# STM32H73x register map
File version: 1.0
CPU: CM7 r0p1, little endian, MPU, FPU, 4 interrupt priority bits
Registers are 32-bit, read-write, reset 0x0 unless marked. A register's access mark holds for its fields unless they carry their own. Offsets are from the block's base; [hi:lo] are bit positions; {n}, {i} and the like mark numbered series; 'fields as' and 'values as' point back to an identical list.

## STK — SysTick timer
Base 0xE000E010
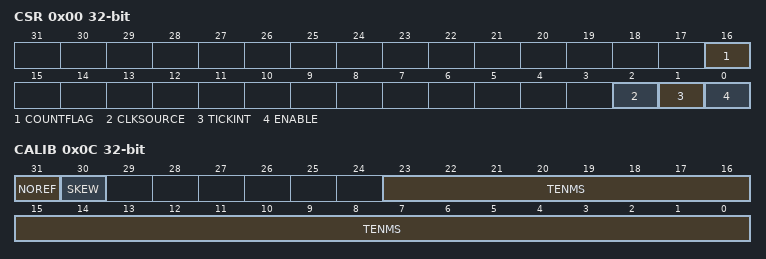
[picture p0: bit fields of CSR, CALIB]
0x00 CSR — SysTick control and status register
  [16] COUNTFLAG
  [2] CLKSOURCE — Clock source selection
  [1] TICKINT — SysTick exception request enable
  [0] ENABLE — Counter enable
0x04 RVR — SysTick reload value register
  [23:0] RELOAD — RELOAD value
0x08 CVR — SysTick current value register
  [23:0] CURRENT — Current counter value
0x0C CALIB — SysTick calibration value register
  [31] NOREF — NOREF flag. Reads as zero
  [30] SKEW — SKEW flag: Indicates whether the TENMS value is exact
  [23:0] TENMS — Calibration value

## NVIC_STIR — Nested vectored interrupt controller
Base 0xE000EF00
0x00 STIR — Software trigger interrupt register
  [8:0] INTID — Software generated interrupt ID

## FPU_CPACR — Floating point unit CPACR
Base 0xE000ED88
0x00 CPACR — Coprocessor access control register
  [23:20] CP

## SCB_ACTRL — System control block ACTLR
Base 0xE000E008
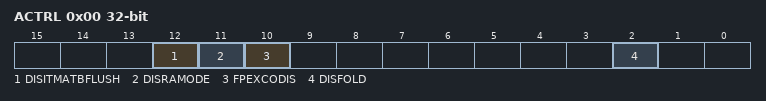
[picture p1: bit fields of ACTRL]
0x00 ACTRL — Auxiliary control register
  [12] DISITMATBFLUSH, [11] DISRAMODE, [10] FPEXCODIS, [2] DISFOLD

## FPU — Floting point unit
Base 0xE000EF34
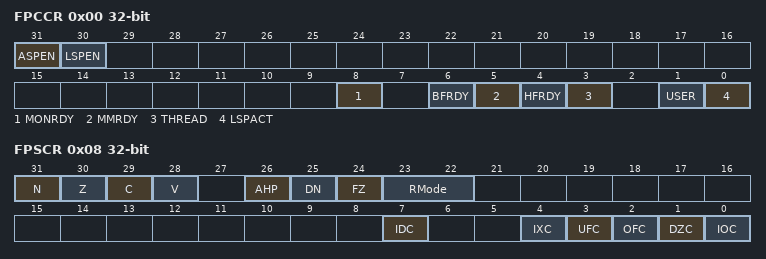
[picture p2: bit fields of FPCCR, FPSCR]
0x00 FPCCR — Floating-point context control register
  [31] ASPEN, [30] LSPEN, [8] MONRDY, [6] BFRDY, [5] MMRDY, [4] HFRDY, [3] THREAD, [1] USER, [0] LSPACT
0x04 FPCAR — Floating-point context address register
  [31:3] ADDRESS — Location of unpopulated floating-point
0x08 FPSCR — Floating-point status control register
  [31] N — Negative condition code flag
  [30] Z — Zero condition code flag
  [29] C — Carry condition code flag
  [28] V — Overflow condition code flag
  [26] AHP — Alternative half-precision control bit
  [25] DN — Default NaN mode control bit
  [24] FZ — Flush-to-zero mode control bit:
  [23:22] RMode — Rounding Mode control field
  [7] IDC — Input denormal cumulative exception bit.
  [4] IXC — Inexact cumulative exception bit
  [3] UFC — Underflow cumulative exception bit
  [2] OFC — Overflow cumulative exception bit
  [1] DZC — Division by zero cumulative exception bit.
  [0] IOC — Invalid operation cumulative exception bit

## PF — Processor features
Base 0xE000ED78
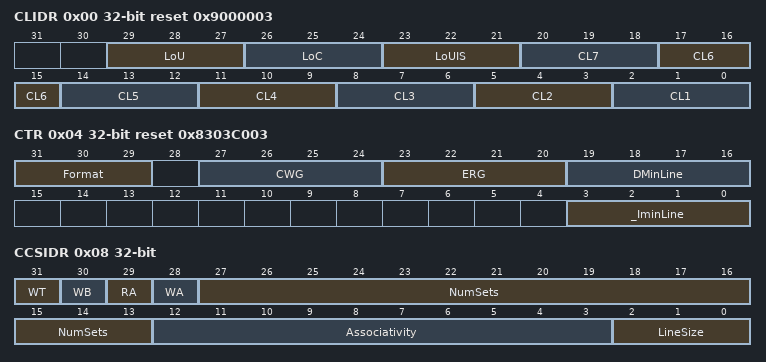
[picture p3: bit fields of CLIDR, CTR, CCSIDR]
0x00 CLIDR ro reset 0x9000003 — Cache Level ID register
  [29:27] LoU, [26:24] LoC, [23:21] LoUIS, [3n-1:3n-3] CL{n} (n=1..7)
0x04 CTR ro reset 0x8303C003 — Cache Type register
  [31:29] Format, [27:24] CWG, [23:20] ERG, [19:16] DMinLine, [3:0] _IminLine
0x08 CCSIDR ro — Cache Size ID register
  [31] WT, [30] WB, [29] RA, [28] WA, [27:13] NumSets, [12:3] Associativity, [2:0] LineSize

## AC — Access control
Base 0xE000EF90
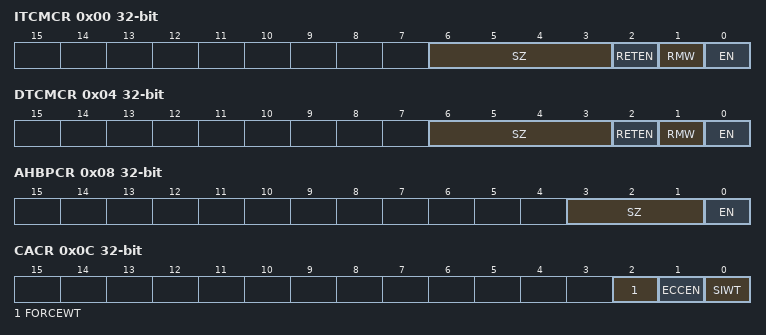
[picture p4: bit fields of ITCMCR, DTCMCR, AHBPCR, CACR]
0x00 ITCMCR — Instruction and Data Tightly-Coupled Memory Control Registers
  [6:3] SZ, [2] RETEN, [1] RMW, [0] EN
0x04 DTCMCR — Instruction and Data Tightly-Coupled Memory Control Registers
  [6:3] SZ, [2] RETEN, [1] RMW, [0] EN
0x08 AHBPCR — AHBP Control register
  [3:1] SZ, [0] EN
0x0C CACR — Auxiliary Cache Control register
  [2] FORCEWT, [1] ECCEN, [0] SIWT
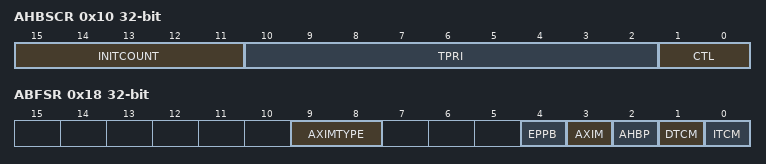
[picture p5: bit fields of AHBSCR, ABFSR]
0x10 AHBSCR — AHB Slave Control register
  [15:11] INITCOUNT, [10:2] TPRI, [1:0] CTL
0x18 ABFSR — Auxiliary Bus Fault Status register
  [9:8] AXIMTYPE, [4] EPPB, [3] AXIM, [2] AHBP, [1] DTCM, [0] ITCM

## RAMECC1 — ECC controller is associated to each RAM area
Base 0x52009000
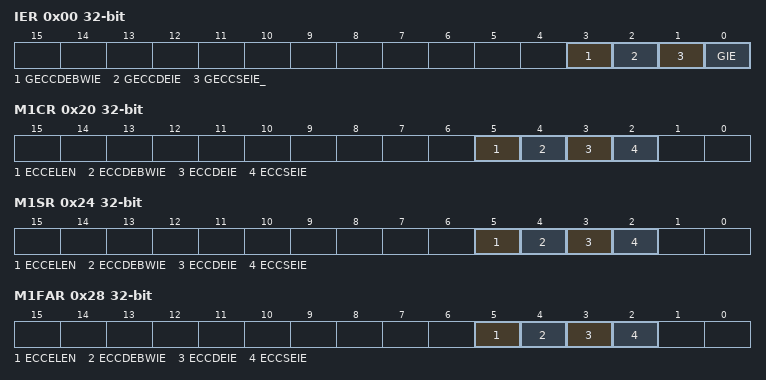
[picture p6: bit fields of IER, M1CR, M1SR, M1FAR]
0x00 IER — RAMECC interrupt enable register
  [3] GECCDEBWIE — Global ECC double error on byte write (BW) interrupt enable
  [2] GECCDEIE — Global ECC double error interrupt enable
  [1] GECCSEIE_ — Global ECC single error interrupt enable
  [0] GIE — Global interrupt enable
0x20 M1CR — RAMECC monitor x configuration register
  [5] ECCELEN — ECC error latching enable
  [4] ECCDEBWIE — ECC double error on byte write (BW) interrupt enable
  [3] ECCDEIE — ECC double error interrupt enable
  [2] ECCSEIE — ECC single error interrupt enable
0x24 M1SR — RAMECC monitor x status register
  fields as M1CR
0x28 M1FAR — RAMECC monitor x failing address register
  fields as M1CR
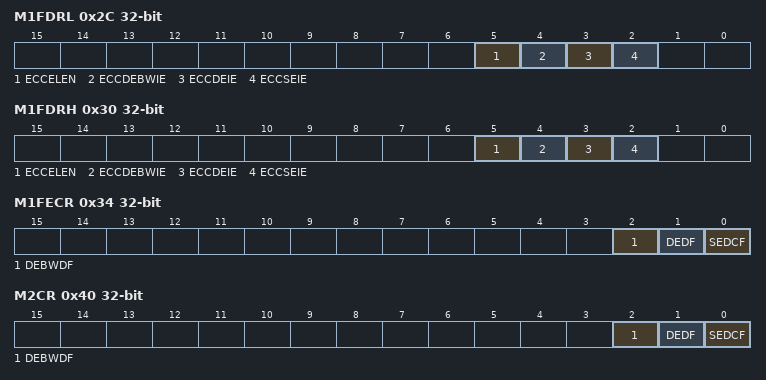
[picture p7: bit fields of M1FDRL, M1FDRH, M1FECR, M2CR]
0x2C M1FDRL — RAMECC monitor x failing data low register
  fields as M1CR
0x30 M1FDRH — RAMECC monitor x failing data high register
  fields as M1CR
0x34 M1FECR — RAMECC monitor x failing ECC error code register
  [2] DEBWDF — ECC double error on byte write (BW) detected flag
  [1] DEDF — ECC double error detected flag
  [0] SEDCF — ECC single error detected and corrected flag
0x40 M2CR — RAMECC monitor x configuration register
  fields as M1FECR
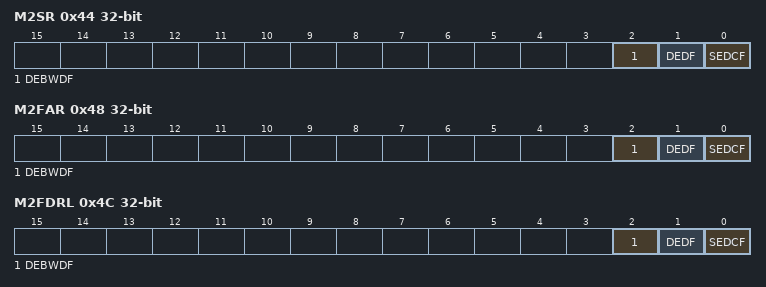
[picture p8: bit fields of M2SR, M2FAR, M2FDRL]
0x44 M2SR — RAMECC monitor x status register
  fields as M1FECR
0x48 M2FAR — RAMECC monitor x failing address register
  fields as M1FECR
0x4C M2FDRL — RAMECC monitor x failing data low register
  fields as M1FECR
0x50 M2FDRH ro — RAMECC monitor x failing data high register
  [31:0] FADD — ECC error failing address
0x58 M2FECR ro — RAMECC monitor x failing ECC error code register
  [31:0] FADD — ECC error failing address
0x60 M3CR ro — RAMECC monitor x configuration register
  [31:0] FADD — ECC error failing address
0x64 M3SR ro — RAMECC monitor x status register
  [31:0] FADD — ECC error failing address
0x68 M3FAR — RAMECC monitor x failing address register
  [31:0] FADD — ECC error failing address
0x6C M3FDRL ro — RAMECC monitor x failing data low register
  [31:0] FDATAL — Failing data low
0x70 M3FDRH ro — RAMECC monitor x failing data high register
  [31:0] FDATAL — Failing data low
0x7C M3FECR ro — RAMECC monitor x failing ECC error code register
  [31:0] FDATAL — Failing data low
0x80 M4CR ro — RAMECC monitor x configuration register
  [31:0] FDATAL — Failing data low
0x84 M4SR ro — RAMECC monitor x status register
  [31:0] FDATAL — Failing data low
0x88 M4FAR ro — RAMECC monitor x failing address register
  [31:0] FDATAH — Failing data high (64-bit memory)
0x8C M4FDRL — RAMECC monitor x failing data low register
  [31:0] FDATAH — Failing data high (64-bit memory)
0x90 M4FDRH ro — RAMECC monitor x failing data high register
  [31:0] FDATAH — Failing data high (64-bit memory)
0x90 M4FECR ro (alternate view of M4FDRH) — RAMECC monitor x failing ECC error code register
  [31:0] FDATAH — Failing data high (64-bit memory)
0xA0 M5CR ro — RAMECC monitor x configuration register
  [31:0] FEC — Failing error code
0xA4 M5SR — RAMECC monitor x status register
  [31:0] FEC — Failing error code
0xA8 M5FAR — RAMECC monitor x failing address register
  [31:0] FEC — Failing error code
0xAC M5FDRL ro — RAMECC monitor x failing data low register
  [31:0] FEC — Failing error code
0xB0 M5FDRH ro — RAMECC monitor x failing data high register
  [31:0] FEC — Failing error code
0xB4 M5FECR ro — RAMECC monitor x failing ECC error code register
  [31:0] FEC — Failing error code
